AUTOSAR XML (schema 4-0-3)
standard types defined: Boolean, UInt16
package /AUTOSAR_Platform/DataConstrs
  range DC_Boolean: raw 0..1
  range DC_UInt16: raw 0..65535
package /PATAC/MSM/ComponentTypes
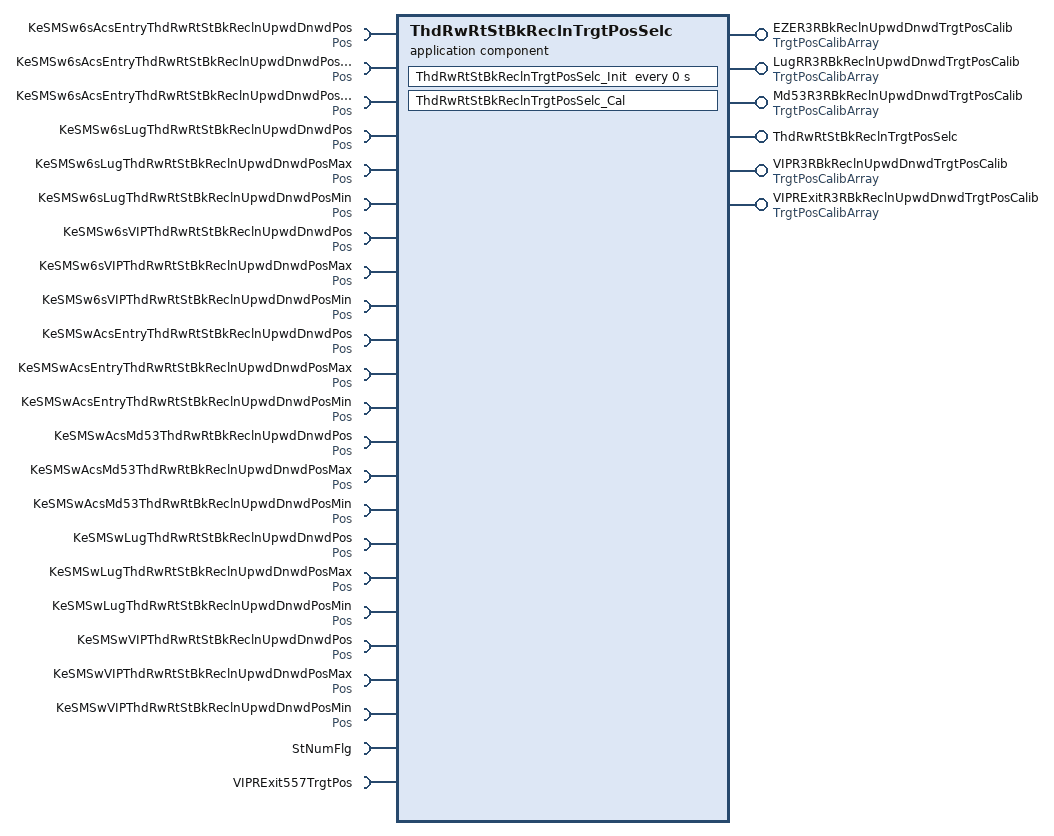
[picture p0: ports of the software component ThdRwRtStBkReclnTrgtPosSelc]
  application sw component type ThdRwRtStBkReclnTrgtPosSelc
    6 x provide port:
      EZER3RBkReclnUpwdDnwdTrgtPosCalib: nonqueued-sender-com-spec{data-element=TrgtPosArray, init-value=[4095, 4095, 4095]}, provided-interface=TrgtPosCalibArray
      LugRR3RBkReclnUpwdDnwdTrgtPosCalib: nonqueued-sender-com-spec{data-element=TrgtPosArray, init-value=[4095, 4095, 4095]}, provided-interface=TrgtPosCalibArray
      Md53R3RBkReclnUpwdDnwdTrgtPosCalib: nonqueued-sender-com-spec{data-element=TrgtPosArray, init-value=[4095, 4095, 4095]}, provided-interface=TrgtPosCalibArray
      ThdRwRtStBkReclnTrgtPosSelc: server-com-spec{operation=Cal, queue-length=1}, provided-interface=ThdRwRtStBkReclnTrgtPosSelc
      VIPR3RBkReclnUpwdDnwdTrgtPosCalib: nonqueued-sender-com-spec{data-element=TrgtPosArray, init-value=[4095, 4095, 4095]}, provided-interface=TrgtPosCalibArray
      VIPRExitR3RBkReclnUpwdDnwdTrgtPosCalib: nonqueued-sender-com-spec{data-element=TrgtPosArray, init-value=[4095, 4095, 4095]}, provided-interface=TrgtPosCalibArray
    23 x require port:
      KeSMSw6sAcsEntryThdRwRtStBkReclnUpwdDnwdPos: parameter-require-com-spec{init-value=2080, parameter=Val}, required-interface=Pos
      KeSMSw6sAcsEntryThdRwRtStBkReclnUpwdDnwdPosMax: parameter-require-com-spec{init-value=2095, parameter=Val}, required-interface=Pos
      KeSMSw6sAcsEntryThdRwRtStBkReclnUpwdDnwdPosMin: parameter-require-com-spec{init-value=2080, parameter=Val}, required-interface=Pos
      KeSMSw6sLugThdRwRtStBkReclnUpwdDnwdPos: parameter-require-com-spec{init-value=0, parameter=Val}, required-interface=Pos
      KeSMSw6sLugThdRwRtStBkReclnUpwdDnwdPosMax: parameter-require-com-spec{init-value=0, parameter=Val}, required-interface=Pos
      KeSMSw6sLugThdRwRtStBkReclnUpwdDnwdPosMin: parameter-require-com-spec{init-value=0, parameter=Val}, required-interface=Pos
      KeSMSw6sVIPThdRwRtStBkReclnUpwdDnwdPos: parameter-require-com-spec{init-value=0, parameter=Val}, required-interface=Pos
      KeSMSw6sVIPThdRwRtStBkReclnUpwdDnwdPosMax: parameter-require-com-spec{init-value=0, parameter=Val}, required-interface=Pos
      KeSMSw6sVIPThdRwRtStBkReclnUpwdDnwdPosMin: parameter-require-com-spec{init-value=0, parameter=Val}, required-interface=Pos
      KeSMSwAcsEntryThdRwRtStBkReclnUpwdDnwdPos: parameter-require-com-spec{init-value=2080, parameter=Val}, required-interface=Pos
      KeSMSwAcsEntryThdRwRtStBkReclnUpwdDnwdPosMax: parameter-require-com-spec{init-value=2095, parameter=Val}, required-interface=Pos
      KeSMSwAcsEntryThdRwRtStBkReclnUpwdDnwdPosMin: parameter-require-com-spec{init-value=2080, parameter=Val}, required-interface=Pos
      KeSMSwAcsMd53ThdRwRtBkReclnUpwdDnwdPos: parameter-require-com-spec{init-value=2080, parameter=Val}, required-interface=Pos
      KeSMSwAcsMd53ThdRwRtBkReclnUpwdDnwdPosMax: parameter-require-com-spec{init-value=2080, parameter=Val}, required-interface=Pos
      KeSMSwAcsMd53ThdRwRtBkReclnUpwdDnwdPosMin: parameter-require-com-spec{init-value=2080, parameter=Val}, required-interface=Pos
      KeSMSwLugThdRwRtStBkReclnUpwdDnwdPos: parameter-require-com-spec{init-value=0, parameter=Val}, required-interface=Pos
      KeSMSwLugThdRwRtStBkReclnUpwdDnwdPosMax: parameter-require-com-spec{init-value=0, parameter=Val}, required-interface=Pos
      KeSMSwLugThdRwRtStBkReclnUpwdDnwdPosMin: parameter-require-com-spec{init-value=0, parameter=Val}, required-interface=Pos
      KeSMSwVIPThdRwRtStBkReclnUpwdDnwdPos: parameter-require-com-spec{init-value=0, parameter=Val}, required-interface=Pos
      KeSMSwVIPThdRwRtStBkReclnUpwdDnwdPosMax: parameter-require-com-spec{init-value=0, parameter=Val}, required-interface=Pos
      KeSMSwVIPThdRwRtStBkReclnUpwdDnwdPosMin: parameter-require-com-spec{init-value=0, parameter=Val}, required-interface=Pos
      StNumFlg: required-interface=StNumFlg
        required-com-specs:
          data-element=Is4s, filter=data-filter-type=ALWAYS, init-value=0
          data-element=Is6s, filter=data-filter-type=ALWAYS, init-value=0
          data-element=Is6s7s, filter=data-filter-type=ALWAYS, init-value=0
          data-element=Is7s, filter=data-filter-type=ALWAYS, init-value=0
      VIPRExit557TrgtPos: required-com-specs=[Get, Set], required-interface=VIPRExit557TrgtPos
    behavior ThdRwRtStBkReclnTrgtPosSelc_InternalBehavior
      operation invoked event OIT_ThdRwRtStBkReclnTrgtPosSelc_Cal_ThdRwRtStBkReclnTrgtPosSelc_Cal: start-on-event=ThdRwRtStBkReclnTrgtPosSelc_Cal, operation=ThdRwRtStBkReclnTrgtPosSelc.Cal
      timing event ThdRwRtStBkReclnTrgtPosSelc_InitEvent: start-on-event=ThdRwRtStBkReclnTrgtPosSelc_Init, period=0
      runnable ThdRwRtStBkReclnTrgtPosSelc_Cal
        data-receive-point-by-arguments:
          4 x access:
            REC_StNumFlg_Is4s: accessed-variable=StNumFlg.Is4s
            REC_StNumFlg_Is6s: accessed-variable=StNumFlg.Is6s
            REC_StNumFlg_Is6s7s: accessed-variable=StNumFlg.Is6s7s
            REC_StNumFlg_Is7s: accessed-variable=StNumFlg.Is7s
        data-send-points:
          5 x access:
            SEND_EZER3RBkReclnUpwdDnwdTrgtPosCalib_TrgtPosArray: accessed-variable=EZER3RBkReclnUpwdDnwdTrgtPosCalib.TrgtPosArray
            SEND_LugRR3RBkReclnUpwdDnwdTrgtPosCalib_TrgtPosArray: accessed-variable=LugRR3RBkReclnUpwdDnwdTrgtPosCalib.TrgtPosArray
            SEND_Md53R3RBkReclnUpwdDnwdTrgtPosCalib_TrgtPosArray: accessed-variable=Md53R3RBkReclnUpwdDnwdTrgtPosCalib.TrgtPosArray
            SEND_VIPR3RBkReclnUpwdDnwdTrgtPosCalib_TrgtPosArray: accessed-variable=VIPR3RBkReclnUpwdDnwdTrgtPosCalib.TrgtPosArray
            SEND_VIPRExitR3RBkReclnUpwdDnwdTrgtPosCalib_TrgtPosArray: accessed-variable=VIPRExitR3RBkReclnUpwdDnwdTrgtPosCalib.TrgtPosArray
        21 x parameter access:
          PA_KeSMSw6sAcsEntryThdRwRtStBkReclnUpwdDnwdPos_Val: accessed-parameter=KeSMSw6sAcsEntryThdRwRtStBkReclnUpwdDnwdPos.Val
          PA_KeSMSw6sAcsEntryThdRwRtStBkReclnUpwdDnwdPosMax_Val: accessed-parameter=KeSMSw6sAcsEntryThdRwRtStBkReclnUpwdDnwdPosMax.Val
          PA_KeSMSw6sAcsEntryThdRwRtStBkReclnUpwdDnwdPosMin_Val: accessed-parameter=KeSMSw6sAcsEntryThdRwRtStBkReclnUpwdDnwdPosMin.Val
          PA_KeSMSw6sLugThdRwRtStBkReclnUpwdDnwdPos_Val: accessed-parameter=KeSMSw6sLugThdRwRtStBkReclnUpwdDnwdPos.Val
          PA_KeSMSw6sLugThdRwRtStBkReclnUpwdDnwdPosMax_Val: accessed-parameter=KeSMSw6sLugThdRwRtStBkReclnUpwdDnwdPosMax.Val
          PA_KeSMSw6sLugThdRwRtStBkReclnUpwdDnwdPosMin_Val: accessed-parameter=KeSMSw6sLugThdRwRtStBkReclnUpwdDnwdPosMin.Val
          PA_KeSMSw6sVIPThdRwRtStBkReclnUpwdDnwdPos_Val: accessed-parameter=KeSMSw6sVIPThdRwRtStBkReclnUpwdDnwdPos.Val
          PA_KeSMSw6sVIPThdRwRtStBkReclnUpwdDnwdPosMax_Val: accessed-parameter=KeSMSw6sVIPThdRwRtStBkReclnUpwdDnwdPosMax.Val
          PA_KeSMSw6sVIPThdRwRtStBkReclnUpwdDnwdPosMin_Val: accessed-parameter=KeSMSw6sVIPThdRwRtStBkReclnUpwdDnwdPosMin.Val
          PA_KeSMSwAcsEntryThdRwRtStBkReclnUpwdDnwdPos_Val: accessed-parameter=KeSMSwAcsEntryThdRwRtStBkReclnUpwdDnwdPos.Val
          PA_KeSMSwAcsEntryThdRwRtStBkReclnUpwdDnwdPosMax_Val: accessed-parameter=KeSMSwAcsEntryThdRwRtStBkReclnUpwdDnwdPosMax.Val
          PA_KeSMSwAcsEntryThdRwRtStBkReclnUpwdDnwdPosMin_Val: accessed-parameter=KeSMSwAcsEntryThdRwRtStBkReclnUpwdDnwdPosMin.Val
          PA_KeSMSwAcsMd53ThdRwRtBkReclnUpwdDnwdPos_Val: accessed-parameter=KeSMSwAcsMd53ThdRwRtBkReclnUpwdDnwdPos.Val
          PA_KeSMSwAcsMd53ThdRwRtBkReclnUpwdDnwdPosMax_Val: accessed-parameter=KeSMSwAcsMd53ThdRwRtBkReclnUpwdDnwdPosMax.Val
          PA_KeSMSwAcsMd53ThdRwRtBkReclnUpwdDnwdPosMin_Val: accessed-parameter=KeSMSwAcsMd53ThdRwRtBkReclnUpwdDnwdPosMin.Val
          PA_KeSMSwLugThdRwRtStBkReclnUpwdDnwdPos_Val: accessed-parameter=KeSMSwLugThdRwRtStBkReclnUpwdDnwdPos.Val
          PA_KeSMSwLugThdRwRtStBkReclnUpwdDnwdPosMax_Val: accessed-parameter=KeSMSwLugThdRwRtStBkReclnUpwdDnwdPosMax.Val
          PA_KeSMSwLugThdRwRtStBkReclnUpwdDnwdPosMin_Val: accessed-parameter=KeSMSwLugThdRwRtStBkReclnUpwdDnwdPosMin.Val
          PA_KeSMSwVIPThdRwRtStBkReclnUpwdDnwdPos_Val: accessed-parameter=KeSMSwVIPThdRwRtStBkReclnUpwdDnwdPos.Val
          PA_KeSMSwVIPThdRwRtStBkReclnUpwdDnwdPosMax_Val: accessed-parameter=KeSMSwVIPThdRwRtStBkReclnUpwdDnwdPosMax.Val
          PA_KeSMSwVIPThdRwRtStBkReclnUpwdDnwdPosMin_Val: accessed-parameter=KeSMSwVIPThdRwRtStBkReclnUpwdDnwdPosMin.Val
        sync call SC_VIPRExit557TrgtPos_Get: operation=VIPRExit557TrgtPos.Get, timeout=0
      runnable ThdRwRtStBkReclnTrgtPosSelc_Init
        21 x parameter access:
          PA_KeSMSw6sAcsEntryThdRwRtStBkReclnUpwdDnwdPos_Val: accessed-parameter=KeSMSw6sAcsEntryThdRwRtStBkReclnUpwdDnwdPos.Val
          PA_KeSMSw6sAcsEntryThdRwRtStBkReclnUpwdDnwdPosMax_Val: accessed-parameter=KeSMSw6sAcsEntryThdRwRtStBkReclnUpwdDnwdPosMax.Val
          PA_KeSMSw6sAcsEntryThdRwRtStBkReclnUpwdDnwdPosMin_Val: accessed-parameter=KeSMSw6sAcsEntryThdRwRtStBkReclnUpwdDnwdPosMin.Val
          PA_KeSMSw6sLugThdRwRtStBkReclnUpwdDnwdPos_Val: accessed-parameter=KeSMSw6sLugThdRwRtStBkReclnUpwdDnwdPos.Val
          PA_KeSMSw6sLugThdRwRtStBkReclnUpwdDnwdPosMax_Val: accessed-parameter=KeSMSw6sLugThdRwRtStBkReclnUpwdDnwdPosMax.Val
          PA_KeSMSw6sLugThdRwRtStBkReclnUpwdDnwdPosMin_Val: accessed-parameter=KeSMSw6sLugThdRwRtStBkReclnUpwdDnwdPosMin.Val
          PA_KeSMSw6sVIPThdRwRtStBkReclnUpwdDnwdPos_Val: accessed-parameter=KeSMSw6sVIPThdRwRtStBkReclnUpwdDnwdPos.Val
          PA_KeSMSw6sVIPThdRwRtStBkReclnUpwdDnwdPosMax_Val: accessed-parameter=KeSMSw6sVIPThdRwRtStBkReclnUpwdDnwdPosMax.Val
          PA_KeSMSw6sVIPThdRwRtStBkReclnUpwdDnwdPosMin_Val: accessed-parameter=KeSMSw6sVIPThdRwRtStBkReclnUpwdDnwdPosMin.Val
          PA_KeSMSwAcsEntryThdRwRtStBkReclnUpwdDnwdPos_Val: accessed-parameter=KeSMSwAcsEntryThdRwRtStBkReclnUpwdDnwdPos.Val
          PA_KeSMSwAcsEntryThdRwRtStBkReclnUpwdDnwdPosMax_Val: accessed-parameter=KeSMSwAcsEntryThdRwRtStBkReclnUpwdDnwdPosMax.Val
          PA_KeSMSwAcsEntryThdRwRtStBkReclnUpwdDnwdPosMin_Val: accessed-parameter=KeSMSwAcsEntryThdRwRtStBkReclnUpwdDnwdPosMin.Val
          PA_KeSMSwAcsMd53ThdRwRtBkReclnUpwdDnwdPos_Val: accessed-parameter=KeSMSwAcsMd53ThdRwRtBkReclnUpwdDnwdPos.Val
          PA_KeSMSwAcsMd53ThdRwRtBkReclnUpwdDnwdPosMax_Val: accessed-parameter=KeSMSwAcsMd53ThdRwRtBkReclnUpwdDnwdPosMax.Val
          PA_KeSMSwAcsMd53ThdRwRtBkReclnUpwdDnwdPosMin_Val: accessed-parameter=KeSMSwAcsMd53ThdRwRtBkReclnUpwdDnwdPosMin.Val
          PA_KeSMSwLugThdRwRtStBkReclnUpwdDnwdPos_Val: accessed-parameter=KeSMSwLugThdRwRtStBkReclnUpwdDnwdPos.Val
          PA_KeSMSwLugThdRwRtStBkReclnUpwdDnwdPosMax_Val: accessed-parameter=KeSMSwLugThdRwRtStBkReclnUpwdDnwdPosMax.Val
          PA_KeSMSwLugThdRwRtStBkReclnUpwdDnwdPosMin_Val: accessed-parameter=KeSMSwLugThdRwRtStBkReclnUpwdDnwdPosMin.Val
          PA_KeSMSwVIPThdRwRtStBkReclnUpwdDnwdPos_Val: accessed-parameter=KeSMSwVIPThdRwRtStBkReclnUpwdDnwdPos.Val
          PA_KeSMSwVIPThdRwRtStBkReclnUpwdDnwdPosMax_Val: accessed-parameter=KeSMSwVIPThdRwRtStBkReclnUpwdDnwdPosMax.Val
          PA_KeSMSwVIPThdRwRtStBkReclnUpwdDnwdPosMin_Val: accessed-parameter=KeSMSwVIPThdRwRtStBkReclnUpwdDnwdPosMin.Val
  swc implementation ThdRwRtStBkReclnTrgtPosSelc_Implementation: behavior=ThdRwRtStBkReclnTrgtPosSelc_InternalBehavior
    code-descriptors:
      code Default: artifact-descriptors=autosar-engineering-object={short-label=Default, category=SWSRC}
package /PATAC/MSM/ModeAdjust/CalPortInterface
  parameter interface Pos
    parameter data prototype Val: sw-calibration-access=READ-WRITE, type=UInt16
package /PATAC/MSM/ModeAdjust/DataType
  impl type TrgtPosCalibArray: category=ARRAY, sw-calibration-access=READ-ONLY, type-emitter=RTE  # 0:pos 1:max 2:min
    element Element: array-size=3, array-size-semantics=FIXED-SIZE, implementation-data-type=UInt16, invalid-value=0
package /PATAC/MSM/ModeAdjust/PortInterface
  client server interface ThdRwRtStBkReclnTrgtPosSelc
    operation Cal
  client server interface VIPRExit557TrgtPos
    operation Get
      10 x arg, all with type=UInt16, direction=OUT, server-argument-impl-policy=USE-ARGUMENT-TYPE:
        SecRwRtStBkReclnTrgtPos
        SecRwRtStZeroTrgtPos
        SecRwRtStLgrstUpwdDnwdTrgtPos
        SecRwRtStLgrstInwdOtwdTrgtPos
        ThdRwLtStBkReclnTrgtPos
        ThdRwLtStFwdBkwdTrgtPos
        ThdRwRtStBkReclnTrgtPos
        ThdRwRtStFwdBkwdTrgtPos
        PassStBkReclnTrgtPos
        PassStFwdBkwdTrgtPos
    operation Set
      10 x arg, all with type=UInt16, direction=IN, server-argument-impl-policy=USE-ARGUMENT-TYPE:
        SecRwLtStBkReclnTrgtPos
        SecRwLtStZeroTrgtPos
        SecRwLtStLgrstUpwdDnwdTrgtPos
        SecRwLtStLgrstInwdOtwdTrgtPos
        ThdRwLtStBkReclnTrgtPos
        ThdRwLtStFwdBkwdTrgtPos
        ThdRwRtStBkReclnTrgtPos
        ThdRwRtStFwdBkwdTrgtPos
        PassStBkReclnTrgtPos
        PassStFwdBkwdTrgtPos
  sender receiver interface StNumFlg
    4 x data, all with type=Boolean:
      Is4s
      Is6s
      Is6s7s
      Is7s
    invalidation-policys:
      data-element=Is4s, handle-invalid=DONT-INVALIDATE
      data-element=Is6s, handle-invalid=DONT-INVALIDATE
      data-element=Is6s7s, handle-invalid=DONT-INVALIDATE
      data-element=Is7s, handle-invalid=DONT-INVALIDATE
  sender receiver interface TrgtPosCalibArray: invalidation-policy{data-element=TrgtPosArray, handle-invalid=DONT-INVALIDATE}
    data TrgtPosArray: type=TrgtPosCalibArray  # 0:Pos 1:Max 2:Min
